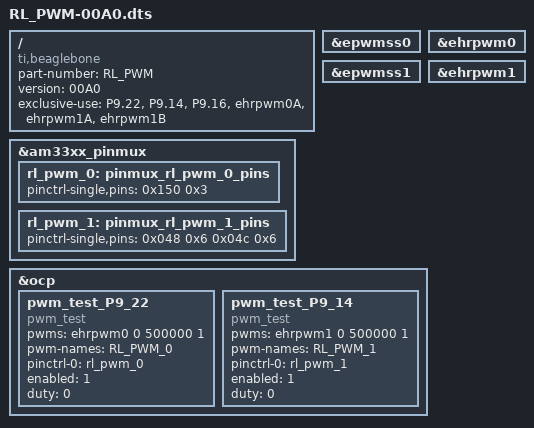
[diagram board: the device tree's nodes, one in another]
/dts-v1/;
/plugin/;

/ {
	compatible = "ti,beaglebone", "ti,beaglebone-green", "ti,beaglebone-black";

	/* identification */
	part-number = "RL_PWM";
	version = "00A0";

	/* state the resources this cape uses */
	exclusive-use =
		/* the pin header uses */
		"P9.22",
		"P9.14",
		"P9.16",
		/* the hardware IP uses */
		"ehrpwm0A",
		"ehrpwm1A",
		"ehrpwm1B";
	
	/* Enable EHRPWM0 and EHRPWM1 */
	fragment@0 {
		target = <&epwmss0>;
		__overlay__ {
			status = "okay";
		};
	};

	fragment@1 {
		target = <&ehrpwm0>;
		__overlay__ {
			status = "okay";
		};
	};
	
	fragment@2 {
		target = <&epwmss1>;
		__overlay__ {
			status = "okay";
		};
	};

	fragment@3 {
		target = <&ehrpwm1>;
		__overlay__ {
			status = "okay";
		};
	};

	/* Set pin muxes */
	fragment@4 {
		target = <&am33xx_pinmux>;
		__overlay__ {
			rl_pwm_0: pinmux_rl_pwm_0_pins {
				pinctrl-single,pins = <
					0x150  0x3
				>;
			};
		};
	};
	
	fragment@5 {
		target = <&am33xx_pinmux>;
		__overlay__ {
			rl_pwm_1: pinmux_rl_pwm_1_pins {
				pinctrl-single,pins = <
					0x048  0x6
					0x04c  0x6
				>;
			};
		};
	};
	
	/* Apply pins to EHRPWM-Modules */
	fragment@6 {
		target = <&ocp>;
		__overlay__ {
			pwm_test_P9_22 {
				compatible	= "pwm_test";
				pwms 		= <&ehrpwm0 0 500000 1>;
				pwm-names 	= "RL_PWM_0";
			    pinctrl-names	= "default";
			    pinctrl-0	= <&rl_pwm_0>;
				enabled		= <1>;
				duty		= <0>;
				status 		= "okay";
			};
		};
	};

	fragment@7 {
		target = <&ocp>;
		__overlay__ {
			pwm_test_P9_14 {
				compatible	= "pwm_test";
				pwms 		= <&ehrpwm1 0 500000 1>;
				pwm-names 	= "RL_PWM_1";
			    pinctrl-names	= "default";
			    pinctrl-0	= <&rl_pwm_1>;
				enabled		= <1>;
				duty		= <0>;
				status 		= "okay";
			};
		};
	};
};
